# NUC1xx_registers register map
File version: 0.1
CPU: 
Registers are 32-bit, read-write, reset 0x0 unless marked. A register's access mark holds for its fields unless they carry their own. Offsets are from the block's base; [hi:lo] are bit positions; lines under a group give offsets from that group; {n}, {i} and the like mark numbered series.

## ADC — Registers group
Base 0x400E0000
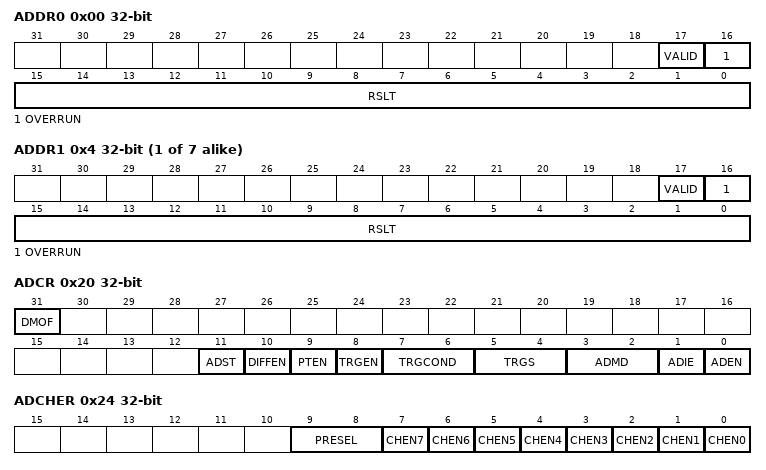
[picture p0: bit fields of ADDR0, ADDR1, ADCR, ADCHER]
0x00 ADDR0 ro — A/D Data Register 0
  [17] VALID — Valid Flag 1 = Data in RSLT[11:0] bits is valid. 0 = Data in RSLT[11:0] bits is not valid. This bit is set to 1 when corresponding channel analog input conversion is completed and cleared by hardware after ADDR register is read.
  [16] OVERRUN — Over Run Flag 1 = Data in RSLT[11:0] is overwrite. 0 = Data in RSLT[11:0] is recent conversion result. If converted data in RSLT[11:0] has not been read before new conversion result is loaded to this register, OVERRUN is set to 1 and previous conversion result is gone. It will be cleared by hardware after ADDR register is read.
  [15:0] RSLT — A/D Conversion Result This field contains conversion result of ADC. For Medium density, RSLT[15:12] always read as 0. For Low density, if DMOF bit (ADCR[31]) set to 0, 12 bits ADC conversion result with unsigned format will be filled in RSLT[11:0] and zero will be filled in RSLT[15:12]. If DMOF bit (ADCR[31]) set to 1, 12 bits ADC conversion result with 2's complement format will be filled in RSLT[11:0] and signed bits will be filled in RSLT[15:12]
{0x0+4i} ADDR{i} ro (i=1..7) — A/D Data Register {i}
  [17] VALID — Valid Flag 1 = Data in RSLT[11:0] bits is valid. 0 = Data in RSLT[11:0] bits is not valid. This bit is set to 1 when corresponding channel analog input conversion is completed and cleared by hardware after ADDR register is read.
  [16] OVERRUN — Over Run Flag 1 = Data in RSLT[11:0] is overwrite. 0 = Data in RSLT[11:0] is recent conversion result. If converted data in RSLT[11:0] has not been read before new conversion result is loaded to this register, OVERRUN is set to 1 and previous conversion result is gone. It will be cleared by hardware after ADDR register is read.
  [15:0] RSLT — A/D Conversion Result This field contains conversion result of ADC. For Medium density, RSLT[15:12] always read as 0. For Low density, if DMOF bit (ADCR[31]) set to 0, 12 bits ADC conversion result with unsigned format will be filled in RSLT[11:0] and zero will be filled in RSLT[15:12]. If DMOF bit (ADCR[31]) set to 1, 12 bits ADC conversion result with 2's complement format will be filled in RSLT[11:0] and signed bits will be filled in RSLT[15:12].
0x20 ADCR — A/D Control Register
  [31] DMOF — A/D differential input Mode Output Format This bit is only supported in Low Density. 1 = A/D Conversion result will be filled in RSLT at ADDRx registers with 2'complement format. 0 = A/D Conversion result will be filled in RSLT at ADDRx registers with unsigned format.
  [11] ADST — A/D Conversion Start 1 = Conversion start. 0 = Conversion stopped and A/D converter enter idle state. ADST bit can be controlled by two sources: software write and external pin STADC. ADST is cleared to 0 by hardware automatically at the ends of single mode and single-cycle scan mode on specified channels. In continuous scan mode, A/D conversion is continuously performed sequentially until this bit is cleared to 0 or chip reset.
  [10] DIFFEN — A/D Differential Input Mode Enable 1 = A/D is in differential analog input mode 0 = A/D is in single-end analog input mode Differential input voltage (Vdiff) = Vplus - Vminus The Vplus of differential input paired channel 0 is from ADC0 pin; Vminus is from ADC1 pin. The Vplus of differential input paired channel 1 is from ADC2 pin; Vminus is from ADC3 pin. The Vplus of differential input paired channel 2 is from ADC4 pin; Vminus is from ADC5 pin. The Vplus of differential input paired channel 3 is from ADC6 pin; Vminus is from ADC7 pin. In differential input mode, only one of the two corresponding channels needs to be enabled in ADCHER. The conversion result will be placed to the corresponding data register of the enabled channel. If both channels of a differential input paired channel are enabled, the ADC will convert it twice in scan mode. And then write the conversion result to the two corresponding data registers.
  [9] PTEN — PDMA Transfer Enable 1 = Enable PDMA data transfer in ADDR 0~7 0 = Disable PDMA data transfer. When A/D conversion is completed, the converted data is loaded into ADDR 0~7, software can enable this bit to generate a PDMA data transfer request. When PTEN=1, software must set ADIE=0 to disable interrupt.
  [8] TRGEN — External Trigger Enable Enable or disable triggering of A/D conversion by external STADC pin. 1= Enable 0= Disable
  [7:6] TRGCOND — External Trigger Condition These two bits decide external pin STADC trigger event is level or edge. The signal must be kept at stable state at least 8 PCLKs for level trigger and 4 PCLKs at high and low state for edge trigger. 00 = Low level 01 = High level 10 = Falling edge 11 = Positive edge
  [5:4] TRGS — Hardware Trigger Source 00 = A/D conversion is started by external STADC pin. Others = Reserved Software should disable TRGE and ADST before change TRGS. In hardware trigger mode, the ADST bit is set by the external trigger from STADC.
  [3:2] ADMD — A/D Converter Operation Mode 00 = Single conversion 01 = Reserved 10 = Single-cycle scan 11 = Continuous scan When changing the operation mode, software should disable ADST bit firstly.
  [1] ADIE — A/D Interrupt Enable 1 = Enable A/D interrupt function 0 = Disable A/D interrupt function A/D conversion end interrupt request is generated if ADIE bit is set to 1.
  [0] ADEN — A/D Converter Enable 1 = Enable 0 = Disable Before starting A/D conversion function, this bit should be set to 1. Clear it to 0 to disable A/D converter analog circuit for saving power consumption.
0x24 ADCHER — A/D Channel Enable Register
  [9:8] PRESEL — Analog Input Channel 7 select 00: External analog input 01: Internal bandgap voltage 10: Internal temperature sensor 11: Reserved
  [n] CHEN{n} (n=1..7) — Analog Input Channel {n} Enable 1 = Enable 0 = Disable
  [0] CHEN0 — Analog Input Channel 0 Enable 1 = Enable 0 = Disable Channel 0 is the default enable channel if CHEN0~7 are set as 0s.
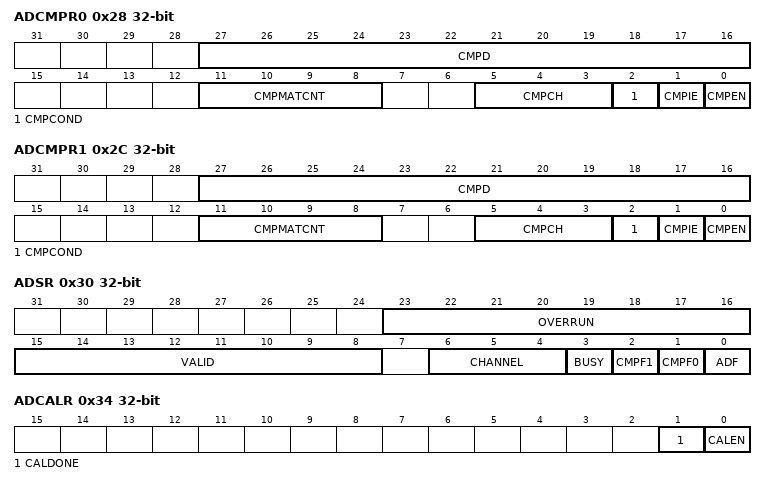
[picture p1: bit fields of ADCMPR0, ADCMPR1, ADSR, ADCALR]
0x28 ADCMPR0 — A/D Compare Register 0
  [27:16] CMPD — Comparison Data The 12 bits data is used to compare with conversion result of specified channel. Software can use it to monitor the external analog input pin voltage transition in scan mode without imposing a load on software. The following description is only supported in Low Density. When DMOF bit is set to 0, ADC comparator compares CMPD with conversion result with unsigned format. CMPD should be filled in unsigned format. When DMOF bit is set to 1, ADC comparator compares CMPD with conversion result with 2's complement format. CMPD should be filled in 2's complement format.
  [11:8] CMPMATCNT — Compare Match Count When the specified A/D channel analog conversion result matches the compare condition defined by CMPCOND[2], the internal match counter will increase 1. When the internal counter reaches the value to (CMPMATCNT +1), the CMPF0 bit will be set.
  [5:3] CMPCH — Compare Channel Selection 000 = Channel 0 conversion result is selected to be compared. 001 = Channel 1 conversion result is selected to be compared. 010 = Channel 2 conversion result is selected to be compared. 011 = Channel 3 conversion result is selected to be compared. 100 = Channel 4 conversion result is selected to be compared. 101 = Channel 5 conversion result is selected to be compared. 110 = Channel 6 conversion result is selected to be compared. 111 = Channel 7 conversion result is selected to be compared.
  [2] CMPCOND — Compare Condition 1 = Set the compare condition as that when a 12-bit A/D conversion result is greater or equal to the 12-bit CMPD (ADCMPR0[27:16]), the internal match counter will increase one. 0 = Set the compare condition as that when a 12-bit A/D conversion result is less than the 12-bit CMPD (ADCMPR0[27:16]), the internal match counter will increase one. When the internal counter reaches the value to (CMPMATCNT +1), the CMPF0 bit will be set.
  [1] CMPIE — Compare Interrupt Enable 1 = Enable 0 = Disable If the compare function is enabled and the compare condition matches the setting of CMPCOND and CMPMATCNT, CMPF0 bit will be asserted, in the meanwhile, if CMPIE is set to 1, a compare interrupt request is generated.
  [0] CMPEN — Compare Enable 1 = Enable compare. 0 = Disable compare. Set this bit to 1 to enable ADC controller to compare CMPD[11:0] with specified channel conversion result when converted data is loaded into ADDR register.
0x2C ADCMPR1 — A/D Compare Register 1
  [27:16] CMPD — Comparison Data The 12 bits data is used to compare with conversion result of specified channel. Software can use it to monitor the external analog input pin voltage transition in scan mode without imposing a load on software. The following description is only supported in Low Density. When DMOF bit is set to 0, ADC comparator compares CMPD with conversion result with unsigned format. CMPD should be filled in unsigned format. When DMOF bit is set to 1, ADC comparator compares CMPD with conversion result with 2's complement format. CMPD should be filled in 2's complement format.
  [11:8] CMPMATCNT — Compare Match Count When the specified A/D channel analog conversion result matches the compare condition defined by CMPCOND[2], the internal match counter will increase 1. When the internal counter reaches the value to (CMPMATCNT +1), the CMPF1 bit will be set.
  [5:3] CMPCH — Compare Channel Selection 000 = Channel 0 conversion result is selected to be compared. 001 = Channel 1 conversion result is selected to be compared. 010 = Channel 2 conversion result is selected to be compared. 011 = Channel 3 conversion result is selected to be compared. 100 = Channel 4 conversion result is selected to be compared. 101 = Channel 5 conversion result is selected to be compared. 110 = Channel 6 conversion result is selected to be compared. 111 = Channel 7 conversion result is selected to be compared.
  [2] CMPCOND — Compare Condition 1 = Set the compare condition as that when a 12-bit A/D conversion result is greater or equal to the 12-bit CMPD (ADCMPR1[27:16]), the internal match counter will increase one. 0 = Set the compare condition as that when a 12-bit A/D conversion result is less than the 12-bit CMPD (ADCMPR1[27:16]), the internal match counter will increase one. When the internal counter reaches the value to (CMPMATCNT +1), the CMPF1 bit will be set.
  [1] CMPIE — Compare Interrupt Enable 1 = Enable 0 = Disable If the compare function is enabled and the compare condition matches the setting of CMPCOND and CMPMATCNT, CMPF1 bit will be asserted, in the meanwhile, if CMPIE is set to 1, a compare interrupt request is generated.
  [0] CMPEN — Compare Enable 1 = Enable compare. 0 = Disable compare. Set this bit to 1 to enable ADC controller to compare CMPD[11:0] with specified channel conversion result when converted data is loaded into ADDR register.
0x30 ADSR — A/D Status Register
  [23:16] OVERRUN ro — Over Run flag It is a mirror of OVERRUN bit in ADDRx It is read only.
  [15:8] VALID ro — Data Valid flag It is a mirror of VALID bit in ADDRx It is read only.
  [6:4] CHANNEL ro — Current Conversion Channel This filed reflects current conversion channel when BUSY=1. When BUSY=0, it shows the next channel will be converted. It is read only.
  [3] BUSY ro — BUSY/IDLE 1 = A/D converter is busy at conversion. 0 = A/D converter is in idle state. This bit is mirror of as ADST bit in ADCR. It is read only.
  [2] CMPF1 write-1-clears — Compare Flag When the selected channel A/D conversion result meets the setting conditions of ADCMPR1 then this bit will be set to 1. And it can be cleared by writing 1 to itself. 1 = Conversion result in ADDR meets ADCMPR1 setting 0 = Conversion result in ADDR does not meet ADCMPR1 setting
  [1] CMPF0 write-1-clears — Compare Flag When the selected channel A/D conversion result meets the setting conditions of ADCMPR0 then this bit will be set to 1. And it can be cleared by writing 1 to itself. 1 = Conversion result in ADDR meets ADCMPR0 setting 0 = Conversion result in ADDR does not meet ADCMPR0 setting
  [0] ADF write-1-clears — A/D Conversion End Flag A status flag that indicates the end of A/D conversion. ADF is set to 1 at these two conditions: When A/D conversion ends in single mode When A/D conversion ends on all specified channels in scan mode. This flag can be cleared by writing 1 to itself.
0x34 ADCALR — A/D Calibration Register
  [1] CALDONE ro — Calibration is Done 1 = A/D converter self calibration is done 0 = A/D converter has not been calibrated or calibration is in progress if CALEN bit is set. When 0 is written to CALEN bit, CALDONE bit is cleared by hardware immediately. It is a read only bit.
  [0] CALEN — Self Calibration Enable 1 = Enable self calibration 0 = Disable self calibration Software can set this bit to 1 enables A/D converter to do self calibration function. It needs 127 ADC clocks to complete calibration. This bit must be kept at 1 after CALDONE asserted. Clearing this bit will disable self calibration function.
0x40 ADPDMA ro — New description for register
  [11:0] AD_PDMA — ADC PDMA current transfer data register When PDMA transferring, read this register can monitor current PDMA transfer data. This is a read only register.
